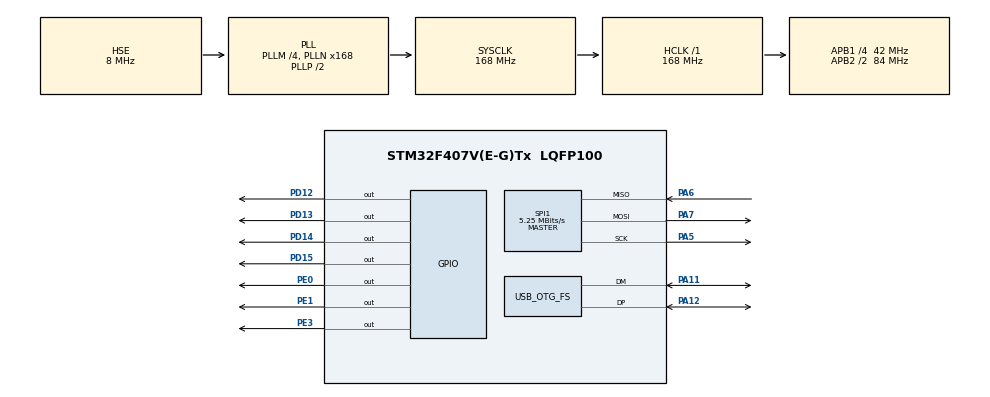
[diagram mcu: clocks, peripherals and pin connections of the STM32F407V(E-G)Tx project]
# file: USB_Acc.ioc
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Mcu.Family=STM32F4
Mcu.Name=STM32F407V(E-G)Tx
Mcu.Package=LQFP100
NVIC.OTG_FS_IRQn=true\:0\:0\:false\:false\:true\:true
NVIC.PriorityGroup=NVIC_PRIORITYGROUP_0
PA11.Mode=Device_Only
PA11.Signal=USB_OTG_FS_DM
PA12.Mode=Device_Only
PA12.Signal=USB_OTG_FS_DP
PA5.Mode=Full_Duplex_Master
PA5.Signal=SPI1_SCK
PA6.Mode=Full_Duplex_Master
PA6.Signal=SPI1_MISO
PA7.Mode=Full_Duplex_Master
PA7.Signal=SPI1_MOSI
PC14-OSC32_IN.Mode=LSE-External-Oscillator
PC14-OSC32_IN.Signal=RCC_OSC32_IN
PC15-OSC32_OUT.Mode=LSE-External-Oscillator
PC15-OSC32_OUT.Signal=RCC_OSC32_OUT
PD12.Signal=GPIO_Output
PD13.Signal=GPIO_Output
PD14.Signal=GPIO_Output
PD15.Signal=GPIO_Output
PE0.Signal=GPIO_Output
PE1.GPIO_Speed=GPIO_SPEED_FREQ_MEDIUM
PE1.Signal=GPIO_Output
PE3.Signal=GPIO_Output
PH0-OSC_IN.Mode=HSE-External-Oscillator
PH0-OSC_IN.Signal=RCC_OSC_IN
PH1-OSC_OUT.Mode=HSE-External-Oscillator
PH1-OSC_OUT.Signal=RCC_OSC_OUT
ProjectManager.HeapSize=0x2000
ProjectManager.StackSize=0x4000
ProjectManager.TargetToolchain=MDK-ARM V5
RCC.48MHZClocksFreq_Value=48000000
RCC.AHBFreq_Value=168000000
RCC.APB1CLKDivider=RCC_HCLK_DIV4
RCC.APB1Freq_Value=42000000
RCC.APB1TimFreq_Value=84000000
RCC.APB2CLKDivider=RCC_HCLK_DIV2
RCC.APB2Freq_Value=84000000
RCC.APB2TimFreq_Value=168000000
RCC.CortexFreq_Value=168000000
RCC.HCLKFreq_Value=168000000
RCC.HSE_VALUE=8000000
RCC.HSI_VALUE=16000000
RCC.PLLM=4
RCC.PLLN=168
RCC.PLLQ=7
RCC.SYSCLKFreq_VALUE=168000000
RCC.SYSCLKSource=RCC_SYSCLKSOURCE_PLLCLK
RCC.VCOOutputFreq_Value=336000000
SPI1.BaudRatePrescaler=SPI_BAUDRATEPRESCALER_16
SPI1.CalculateBaudRate=5.25 MBits/s
SPI1.Direction=SPI_DIRECTION_2LINES
SPI1.Mode=SPI_MODE_MASTER
SPI1.VirtualType=VM_MASTER
USB_DEVICE.CLASS_NAME_FS=CDC
USB_DEVICE.VirtualMode-CDC_FS=Cdc
USB_DEVICE.VirtualModeFS=Cdc_FS
USB_OTG_FS.VirtualMode=Device_Only
VP_USB_DEVICE_VS_USB_DEVICE_CDC_FS.Mode=CDC_FS
board=STM32F4DISCOVERY

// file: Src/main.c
/**
  ******************************************************************************
  * @file           : main.c
  * @brief          : Main program body
  ******************************************************************************
  * This notice applies to any and all portions of this file
  * that are not between comment pairs USER CODE BEGIN and
  * USER CODE END. Other portions of this file, whether
  * inserted by the user or by software development tools
  * are owned by their respective copyright owners.
  *
  * Copyright (c) 2018 STMicroelectronics International N.V.
  * All rights reserved.
  *
  * Redistribution and use in source and binary forms, with or without
  * modification, are permitted, provided that the following conditions are met:
  *
  * 1. Redistribution of source code must retain the above copyright notice,
  *    this list of conditions and the following disclaimer.
  * 2. Redistributions in binary form must reproduce the above copyright notice,
  *    this list of conditions and the following disclaimer in the documentation
  *    and/or other materials provided with the distribution.
  * 3. Neither the name of STMicroelectronics nor the names of other
  *    contributors to this software may be used to endorse or promote products
  *    derived from this software without specific written permission.
  * 4. This software, including modifications and/or derivative works of this
  *    software, must execute solely and exclusively on microcontroller or
  *    microprocessor devices manufactured by or for STMicroelectronics.
  * 5. Redistribution and use of this software other than as permitted under
  *    this license is void and will automatically terminate your rights under
  *    this license.
  *
  * THIS SOFTWARE IS PROVIDED BY STMICROELECTRONICS AND CONTRIBUTORS "AS IS"
  * AND ANY EXPRESS, IMPLIED OR STATUTORY WARRANTIES, INCLUDING, BUT NOT
  * LIMITED TO, THE IMPLIED WARRANTIES OF MERCHANTABILITY, FITNESS FOR A
  * PARTICULAR PURPOSE AND NON-INFRINGEMENT OF THIRD PARTY INTELLECTUAL PROPERTY
  * RIGHTS ARE DISCLAIMED TO THE FULLEST EXTENT PERMITTED BY LAW. IN NO EVENT
  * SHALL STMICROELECTRONICS OR CONTRIBUTORS BE LIABLE FOR ANY DIRECT, INDIRECT,
  * INCIDENTAL, SPECIAL, EXEMPLARY, OR CONSEQUENTIAL DAMAGES (INCLUDING, BUT NOT
  * LIMITED TO, PROCUREMENT OF SUBSTITUTE GOODS OR SERVICES; LOSS OF USE, DATA,
  * OR PROFITS; OR BUSINESS INTERRUPTION) HOWEVER CAUSED AND ON ANY THEORY OF
  * LIABILITY, WHETHER IN CONTRACT, STRICT LIABILITY, OR TORT (INCLUDING
  * NEGLIGENCE OR OTHERWISE) ARISING IN ANY WAY OUT OF THE USE OF THIS SOFTWARE,
  * EVEN IF ADVISED OF THE POSSIBILITY OF SUCH DAMAGE.
  *
  ******************************************************************************
  */
#include "main.h"
#include "stm32f4xx_hal.h"
#include "usb_device.h"

/* USER CODE BEGIN Includes */
#include "usbd_cdc_if.h"
#include "lis3dsh.h"
/* USER CODE END Includes */

SPI_HandleTypeDef hspi1;

/* USER CODE BEGIN PV */
/* Private variables ---------------------------------------------------------*/
uint8_t val = 0x00;
/* USER CODE END PV */

void SystemClock_Config(void);
static void MX_GPIO_Init(void);
static void MX_SPI1_Init(void);

/* USER CODE BEGIN PFP */
/* Private function prototypes -----------------------------------------------*/

/* USER CODE END PFP */

int main(void)
{
  /* USER CODE BEGIN 1 */
char str_tx[21] = "hello_world";
  /* USER CODE END 1 */

  /* MCU Configuration----------------------------------------------------------*/

  /* Reset of all peripherals, Initializes the Flash interface and the Systick. */
  HAL_Init();

  /* Configure the system clock */
  SystemClock_Config();

  /* Initialize all configured peripherals */
  MX_GPIO_Init();
  MX_USB_DEVICE_Init();
  MX_SPI1_Init();
  /* USER CODE BEGIN 2 */

	Accel_Ini();
	Accel_IO_Read(&val, 0x18, 1);
  /* USER CODE END 2 */

  /* Infinite loop */
  while (1)
  {

  /* USER CODE BEGIN 3 */
//CDC_Transmit_FS((unsigned char*)str_tx, strlen(str_tx));

                //HAL_Delay(500);
		Accel_ReadAcc();
  }
  /* USER CODE END 3 */

}

void SystemClock_Config(void)
{

  RCC_OscInitTypeDef RCC_OscInitStruct;
  RCC_ClkInitTypeDef RCC_ClkInitStruct;

    /**Configure the main internal regulator output voltage
    */
  __HAL_RCC_PWR_CLK_ENABLE();

  __HAL_PWR_VOLTAGESCALING_CONFIG(PWR_REGULATOR_VOLTAGE_SCALE1);

    /**Initializes the CPU, AHB and APB busses clocks
    */
  RCC_OscInitStruct.OscillatorType = RCC_OSCILLATORTYPE_HSE;
  RCC_OscInitStruct.HSEState = RCC_HSE_ON;
  RCC_OscInitStruct.PLL.PLLState = RCC_PLL_ON;
  RCC_OscInitStruct.PLL.PLLSource = RCC_PLLSOURCE_HSE;
  RCC_OscInitStruct.PLL.PLLM = 4;
  RCC_OscInitStruct.PLL.PLLN = 168;
  RCC_OscInitStruct.PLL.PLLP = RCC_PLLP_DIV2;
  RCC_OscInitStruct.PLL.PLLQ = 7;
  if (HAL_RCC_OscConfig(&RCC_OscInitStruct) != HAL_OK)
  {
    _Error_Handler(__FILE__, __LINE__);
  }

    /**Initializes the CPU, AHB and APB busses clocks
    */
  RCC_ClkInitStruct.ClockType = RCC_CLOCKTYPE_HCLK|RCC_CLOCKTYPE_SYSCLK
                              |RCC_CLOCKTYPE_PCLK1|RCC_CLOCKTYPE_PCLK2;
  RCC_ClkInitStruct.SYSCLKSource = RCC_SYSCLKSOURCE_PLLCLK;
  RCC_ClkInitStruct.AHBCLKDivider = RCC_SYSCLK_DIV1;
  RCC_ClkInitStruct.APB1CLKDivider = RCC_HCLK_DIV4;
  RCC_ClkInitStruct.APB2CLKDivider = RCC_HCLK_DIV2;

  if (HAL_RCC_ClockConfig(&RCC_ClkInitStruct, FLASH_LATENCY_5) != HAL_OK)
  {
    _Error_Handler(__FILE__, __LINE__);
  }

    /**Configure the Systick interrupt time
    */
  HAL_SYSTICK_Config(HAL_RCC_GetHCLKFreq()/1000);

    /**Configure the Systick
    */
  HAL_SYSTICK_CLKSourceConfig(SYSTICK_CLKSOURCE_HCLK);

  /* SysTick_IRQn interrupt configuration */
  HAL_NVIC_SetPriority(SysTick_IRQn, 0, 0);
}

/* SPI1 init function */
static void MX_SPI1_Init(void)
{

  /* SPI1 parameter configuration*/
  hspi1.Instance = SPI1;
  hspi1.Init.Mode = SPI_MODE_MASTER;
  hspi1.Init.Direction = SPI_DIRECTION_2LINES;
  hspi1.Init.DataSize = SPI_DATASIZE_8BIT;
  hspi1.Init.CLKPolarity = SPI_POLARITY_LOW;
  hspi1.Init.CLKPhase = SPI_PHASE_1EDGE;
  hspi1.Init.NSS = SPI_NSS_SOFT;
  hspi1.Init.BaudRatePrescaler = SPI_BAUDRATEPRESCALER_16;
  hspi1.Init.FirstBit = SPI_FIRSTBIT_MSB;
  hspi1.Init.TIMode = SPI_TIMODE_DISABLE;
  hspi1.Init.CRCCalculation = SPI_CRCCALCULATION_DISABLE;
  hspi1.Init.CRCPolynomial = 10;
  if (HAL_SPI_Init(&hspi1) != HAL_OK)
  {
    _Error_Handler(__FILE__, __LINE__);
  }

}

/** Configure pins as
        * Analog
        * Input
        * Output
        * EVENT_OUT
        * EXTI
*/
static void MX_GPIO_Init(void)
{

  GPIO_InitTypeDef GPIO_InitStruct;

  /* GPIO Ports Clock Enable */
  __HAL_RCC_GPIOE_CLK_ENABLE();
  __HAL_RCC_GPIOC_CLK_ENABLE();
  __HAL_RCC_GPIOH_CLK_ENABLE();
  __HAL_RCC_GPIOA_CLK_ENABLE();
  __HAL_RCC_GPIOD_CLK_ENABLE();

  /*Configure GPIO pin Output Level */
  HAL_GPIO_WritePin(GPIOE, GPIO_PIN_3|GPIO_PIN_0|GPIO_PIN_1, GPIO_PIN_RESET);

  /*Configure GPIO pin Output Level */
  HAL_GPIO_WritePin(GPIOD, GPIO_PIN_12|GPIO_PIN_13|GPIO_PIN_14|GPIO_PIN_15, GPIO_PIN_RESET);

  /*Configure GPIO pins : PE3 PE0 */
  GPIO_InitStruct.Pin = GPIO_PIN_3|GPIO_PIN_0;
  GPIO_InitStruct.Mode = GPIO_MODE_OUTPUT_PP;
  GPIO_InitStruct.Pull = GPIO_NOPULL;
  GPIO_InitStruct.Speed = GPIO_SPEED_FREQ_LOW;
  HAL_GPIO_Init(GPIOE, &GPIO_InitStruct);

  /*Configure GPIO pins : PD12 PD13 PD14 PD15 */
  GPIO_InitStruct.Pin = GPIO_PIN_12|GPIO_PIN_13|GPIO_PIN_14|GPIO_PIN_15;
  GPIO_InitStruct.Mode = GPIO_MODE_OUTPUT_PP;
  GPIO_InitStruct.Pull = GPIO_NOPULL;
  GPIO_InitStruct.Speed = GPIO_SPEED_FREQ_LOW;
  HAL_GPIO_Init(GPIOD, &GPIO_InitStruct);

  /*Configure GPIO pin : PE1 */
  GPIO_InitStruct.Pin = GPIO_PIN_1;
  GPIO_InitStruct.Mode = GPIO_MODE_OUTPUT_PP;
  GPIO_InitStruct.Pull = GPIO_NOPULL;
  GPIO_InitStruct.Speed = GPIO_SPEED_FREQ_MEDIUM;
  HAL_GPIO_Init(GPIOE, &GPIO_InitStruct);

}

void _Error_Handler(char *file, int line)
{
  while(1)
  {
  }
}

/************************ (C) COPYRIGHT STMicroelectronics *****END OF FILE****/
